AUTOSAR XML (schema 4-0-3)
package /ComponentTypes
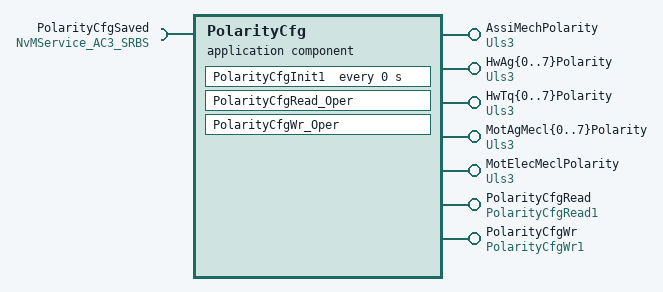
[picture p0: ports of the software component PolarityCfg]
  application sw component type PolarityCfg
    28 x provide port:
      AssiMechPolarity: nonqueued-sender-com-spec{data-element=Val, init-value=1}, provided-interface=Uls3
      HwAg{0..7}Polarity: nonqueued-sender-com-spec{data-element=Val, init-value=1}, provided-interface=Uls3
      HwTq{0..7}Polarity: nonqueued-sender-com-spec{data-element=Val, init-value=1}, provided-interface=Uls3
      MotAgMecl{0..7}Polarity: nonqueued-sender-com-spec{data-element=Val, init-value=1}, provided-interface=Uls3
      MotElecMeclPolarity: nonqueued-sender-com-spec{data-element=Val, init-value=1}, provided-interface=Uls3
      PolarityCfgRead: server-com-spec{operation=Oper, queue-length=1}, provided-interface=PolarityCfgRead1
      PolarityCfgWr: server-com-spec{operation=Oper, queue-length=1}, provided-interface=PolarityCfgWr1
    require port PolarityCfgSaved: required-interface=NvMService_AC3_SRBS
    behavior PolarityCfg_InternalBehavior: data-type-mapping=Nexteer
      ar-typed-per-instance-memorys:
        data PolarityCfgSaved: sw-calibration-access=READ-ONLY, type=Cnt15
      timing event PolarityCfg_InitEvent: start-on-event=PolarityCfgInit1, period=0
      operation invoked event OIT_PolarityCfgRead_Oper_PolarityCfgRead_Oper: start-on-event=PolarityCfgRead_Oper, operation=PolarityCfgRead.Oper
      operation invoked event OIT_PolarityCfgWr_Oper_PolarityCfgWr_Oper: start-on-event=PolarityCfgWr_Oper, operation=PolarityCfgWr.Oper
      runnable PolarityCfgInit1
        data-send-points:
          26 x access:
            SEND_AssiMechPolarity_Val: accessed-variable=AssiMechPolarity.Val
            SEND_HwAg{0..7}Polarity_Val: accessed-variable=HwAg{0..7}Polarity.Val
            SEND_HwTq{0..7}Polarity_Val: accessed-variable=HwTq{0..7}Polarity.Val
            SEND_MotAgMecl{0..7}Polarity_Val: accessed-variable=MotAgMecl{0..7}Polarity.Val
            SEND_MotElecMeclPolarity_Val: accessed-variable=MotElecMeclPolarity.Val
      runnable PolarityCfgRead_Oper
      runnable PolarityCfgWr_Oper
        sync call SC_PolarityCfgSaved_SetRamBlockStatus: operation=PolarityCfgSaved.SetRamBlockStatus, timeout=0
  swc implementation PolarityCfg_Implementation: behavior=PolarityCfg_InternalBehavior
    code-descriptors:
      code Default: artifact-descriptors=autosar-engineering-object={short-label=Default, category=SWSRC}
